# LKS32MC08x register map
Vendor: Linko Ltd.; Series: LKS32MC08x; File version: 1.0
CPU: CM0 r1p0, little endian, MPU, no FPU, 3 interrupt priority bits
Registers are 32-bit, read-write, reset 0x0 unless marked. A register's access mark holds for its fields unless they carry their own. Offsets are from the block's base; [hi:lo] are bit positions; 'fields as' and 'values as' point back to an identical list.

## TIMER1 — TIMER1 registers
Base 0x40011820
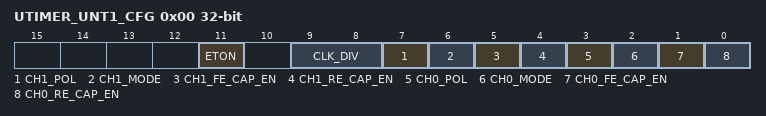
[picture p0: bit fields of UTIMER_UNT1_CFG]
0x00 UTIMER_UNT1_CFG — Timer configuration
  [11] ETON — Timer external trigger
    0=IT (Free run); 1=ET (Extrenal trigger)
  [9:8] CLK_DIV — Timer clock division ratio
  [7] CH1_POL — Channel 1 output polarity at zero-crossing in comparision mode
    0=L (Output 0); 1=H (Output 1)
  [6] CH1_MODE — Channel 1 mode
    0=CMP (Comparison mode); 1=CAP (Capture mode)
  [5] CH1_FE_CAP_EN — Channel 1 falling edge capture enable
    0=Disabled (Falling edge event disabled); 1=Enabled (Falling edge event enabled)
  [4] CH1_RE_CAP_EN — Channel 1 rising edge capture enable
    0=Disabled (Rising edge event disabled); 1=Enabled (Rising edge event enabled)
  [3] CH0_POL — Channel 0 output polarity at zero-crossing in comparision mode
    0=L (Output 0); 1=H (Output 1)
  [2] CH0_MODE — Channel 0 mode
    0=CMP (Comparison mode); 1=CAP (Capture mode)
  [1] CH0_FE_CAP_EN — Channel 0 falling edge capture enable
    values as CH1_FE_CAP_EN
  [0] CH0_RE_CAP_EN — Channel 0 rising edge capture enable
    values as CH1_RE_CAP_EN
0x04 UTIMER_UNT1_TH — Timer counter threshold, timer will count from 0 to TH, then over again
0x08 UTIMER_UNT1_CNT — Timer current counter value (write to set)
0x0C UTIMER_UNT1_CMP0 — Timer Channel0 CMP/CAP threshold
0x10 UTIMER_UNT1_CMP1 — Timer Channel1 CMP/CAP threshold
0x14 UTIMER_UNT1_EVT — Timer External Trigger Event
  [2:0] EVT_SRC — external event select
    0=MCPWM_TADC2 (Use MCPWM TADC2 as trigger); 1=MCPWM_TADC3 (Use MCPWM TADC3 as trigger); 2=T1_CH0 (Use timer1 channel 0 as trigger); 3=T1_CH1 (Use timer1 channel 1 as trigger); 4=T2_CH0 (Use timer2 channel 0 as trigger); 5=T2_CH1 (Use timer2 channel 1 as trigger); 7=T3_CH1 (Use timer3 channel 0 as trigger); 6=T3_CH0 (Use timer3 channel 1 as trigger)

## TIMER2 — TIMER2 registers
Base 0x40011840
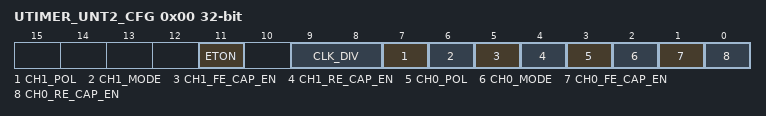
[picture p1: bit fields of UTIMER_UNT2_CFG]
0x00 UTIMER_UNT2_CFG — Timer configuration
  [11] ETON — Timer external trigger
    0=IT (Free run); 1=ET (Extrenal trigger)
  [9:8] CLK_DIV — Timer clock division ratio
  [7] CH1_POL — Channel 1 output polarity at zero-crossing in comparision mode
    0=L (Output 0); 1=H (Output 1)
  [6] CH1_MODE — Channel 1 mode
    0=CMP (Comparison mode); 1=CAP (Capture mode)
  [5] CH1_FE_CAP_EN — Channel 1 falling edge capture enable
    0=Disabled (Falling edge event disabled); 1=Enabled (Falling edge event enabled)
  [4] CH1_RE_CAP_EN — Channel 1 rising edge capture enable
    0=Disabled (Rising edge event disabled); 1=Enabled (Rising edge event enabled)
  [3] CH0_POL — Channel 0 output polarity at zero-crossing in comparision mode
    0=L (Output 0); 1=H (Output 1)
  [2] CH0_MODE — Channel 0 mode
    0=CMP (Comparison mode); 1=CAP (Capture mode)
  [1] CH0_FE_CAP_EN — Channel 0 falling edge capture enable
    values as CH1_FE_CAP_EN
  [0] CH0_RE_CAP_EN — Channel 0 rising edge capture enable
    values as CH1_RE_CAP_EN
0x04 UTIMER_UNT2_TH — Timer counter threshold, timer will count from 0 to TH, then over again
0x08 UTIMER_UNT2_CNT — Timer current counter value (write to set)
0x0C UTIMER_UNT2_CMP0 — Timer Channel0 CMP/CAP threshold
0x10 UTIMER_UNT2_CMP1 — Timer Channel1 CMP/CAP threshold
0x14 UTIMER_UNT2_EVT — Timer External Trigger Event
  [2:0] EVT_SRC — external event select
    0=MCPWM_TADC2 (Use MCPWM TADC2 as trigger); 1=MCPWM_TADC3 (Use MCPWM TADC3 as trigger); 2=T1_CH0 (Use timer1 channel 0 as trigger); 3=T1_CH1 (Use timer1 channel 1 as trigger); 4=T2_CH0 (Use timer2 channel 0 as trigger); 5=T2_CH1 (Use timer2 channel 1 as trigger); 7=T3_CH1 (Use timer3 channel 0 as trigger); 6=T3_CH0 (Use timer3 channel 1 as trigger)

## TIMER3 — TIMER3 registers
Base 0x40011860
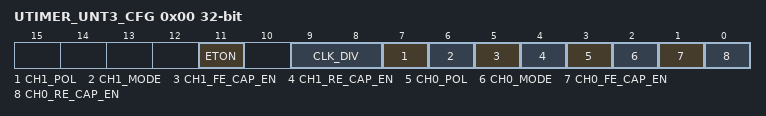
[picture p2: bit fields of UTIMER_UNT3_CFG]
0x00 UTIMER_UNT3_CFG — Timer configuration
  [11] ETON — Timer external trigger
    0=IT (Free run); 1=ET (Extrenal trigger)
  [9:8] CLK_DIV — Timer clock division ratio
  [7] CH1_POL — Channel 1 output polarity at zero-crossing in comparision mode
    0=L (Output 0); 1=H (Output 1)
  [6] CH1_MODE — Channel 1 mode
    0=CMP (Comparison mode); 1=CAP (Capture mode)
  [5] CH1_FE_CAP_EN — Channel 1 falling edge capture enable
    0=Disabled (Falling edge event disabled); 1=Enabled (Falling edge event enabled)
  [4] CH1_RE_CAP_EN — Channel 1 rising edge capture enable
    0=Disabled (Rising edge event disabled); 1=Enabled (Rising edge event enabled)
  [3] CH0_POL — Channel 0 output polarity at zero-crossing in comparision mode
    0=L (Output 0); 1=H (Output 1)
  [2] CH0_MODE — Channel 0 mode
    0=CMP (Comparison mode); 1=CAP (Capture mode)
  [1] CH0_FE_CAP_EN — Channel 0 falling edge capture enable
    values as CH1_FE_CAP_EN
  [0] CH0_RE_CAP_EN — Channel 0 rising edge capture enable
    values as CH1_RE_CAP_EN
0x04 UTIMER_UNT3_TH — Timer counter threshold, timer will count from 0 to TH, then over again
0x08 UTIMER_UNT3_CNT — Timer current counter value (write to set)
0x0C UTIMER_UNT3_CMP0 — Timer Channel0 CMP/CAP threshold
0x10 UTIMER_UNT3_CMP1 — Timer Channel1 CMP/CAP threshold
0x14 UTIMER_UNT3_EVT — Timer External Trigger Event
  [2:0] EVT_SRC — external event select
    0=MCPWM_TADC2 (Use MCPWM TADC2 as trigger); 1=MCPWM_TADC3 (Use MCPWM TADC3 as trigger); 2=T1_CH0 (Use timer1 channel 0 as trigger); 3=T1_CH1 (Use timer1 channel 1 as trigger); 4=T2_CH0 (Use timer2 channel 0 as trigger); 5=T2_CH1 (Use timer2 channel 1 as trigger); 7=T3_CH1 (Use timer3 channel 0 as trigger); 6=T3_CH0 (Use timer3 channel 1 as trigger)
